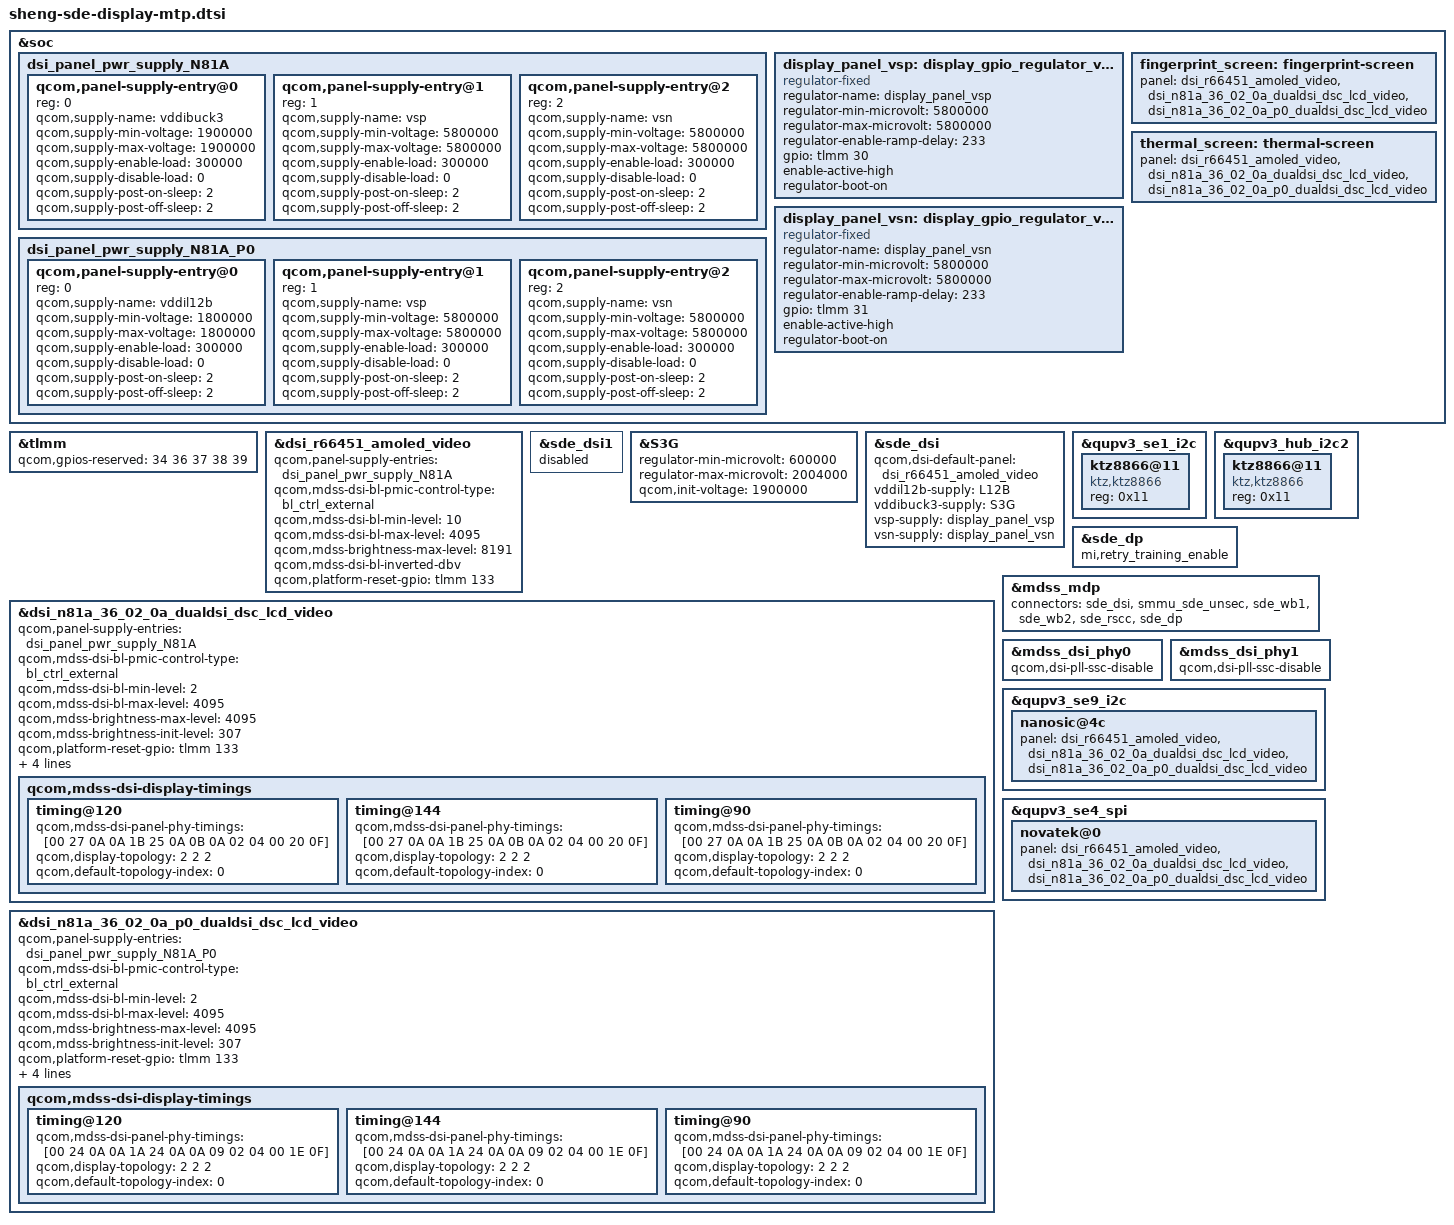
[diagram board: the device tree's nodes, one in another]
#include "kalama-sde-display.dtsi"
#include "dsi-panel-n81a-36-02-0a-dualdsi-dsc-lcd-video.dtsi"
#include "dsi-panel-n81a-36-02-0a-p0-dualdsi-dsc-lcd-video.dtsi"

&soc {
    dsi_panel_pwr_supply_N81A: dsi_panel_pwr_supply_N81A {
        #address-cells = <1>;
        #size-cells = <0>;
        qcom,panel-supply-entry@0 {
            reg = <0>;
            qcom,supply-name = "vddibuck3";
            qcom,supply-min-voltage = <1900000>;
            qcom,supply-max-voltage = <1900000>;
            qcom,supply-enable-load = <300000>;
            qcom,supply-disable-load = <0>;
            qcom,supply-post-on-sleep = <2>;
            qcom,supply-post-off-sleep = <2>;
        };
        qcom,panel-supply-entry@1 {
            reg = <1>;
            qcom,supply-name = "vsp";
            qcom,supply-min-voltage = <5800000>;
            qcom,supply-max-voltage = <5800000>;
            qcom,supply-enable-load = <300000>;
            qcom,supply-disable-load = <0>;
            qcom,supply-post-on-sleep = <2>;
            qcom,supply-post-off-sleep = <2>;
        };
        qcom,panel-supply-entry@2 {
            reg = <2>;
            qcom,supply-name = "vsn";
            qcom,supply-min-voltage = <5800000>;
            qcom,supply-max-voltage = <5800000>;
            qcom,supply-enable-load = <300000>;
            qcom,supply-disable-load = <0>;
            qcom,supply-post-on-sleep = <2>;
            qcom,supply-post-off-sleep = <2>;
        };
    };

    dsi_panel_pwr_supply_N81A_P0: dsi_panel_pwr_supply_N81A_P0 {
        #address-cells = <1>;
        #size-cells = <0>;
        qcom,panel-supply-entry@0 {
            reg = <0>;
            qcom,supply-name = "vddil12b";
            qcom,supply-min-voltage = <1800000>;
            qcom,supply-max-voltage = <1800000>;
            qcom,supply-enable-load = <300000>;
            qcom,supply-disable-load = <0>;
            qcom,supply-post-on-sleep = <2>;
            qcom,supply-post-off-sleep = <2>;
        };
        qcom,panel-supply-entry@1 {
            reg = <1>;
            qcom,supply-name = "vsp";
            qcom,supply-min-voltage = <5800000>;
            qcom,supply-max-voltage = <5800000>;
            qcom,supply-enable-load = <300000>;
            qcom,supply-disable-load = <0>;
            qcom,supply-post-on-sleep = <2>;
            qcom,supply-post-off-sleep = <2>;
        };
        qcom,panel-supply-entry@2 {
            reg = <2>;
            qcom,supply-name = "vsn";
            qcom,supply-min-voltage = <5800000>;
            qcom,supply-max-voltage = <5800000>;
            qcom,supply-enable-load = <300000>;
            qcom,supply-disable-load = <0>;
            qcom,supply-post-on-sleep = <2>;
            qcom,supply-post-off-sleep = <2>;
        };
    };
};

&soc {
    display_panel_vsp: display_gpio_regulator_vsp {
        compatible = "regulator-fixed";
        regulator-name = "display_panel_vsp";
        regulator-min-microvolt = <5800000>;
        regulator-max-microvolt = <5800000>;
        regulator-enable-ramp-delay = <233>;
        gpio = <&tlmm 30 0>;
        enable-active-high;
        regulator-boot-on;
    };

    display_panel_vsn: display_gpio_regulator_vsn {
        compatible = "regulator-fixed";
        regulator-name = "display_panel_vsn";
        regulator-min-microvolt = <5800000>;
        regulator-max-microvolt = <5800000>;
        regulator-enable-ramp-delay = <233>;
        gpio = <&tlmm 31 0>;
        enable-active-high;
        regulator-boot-on;
    };
};

&tlmm {
    qcom,gpios-reserved = <34 36 37 38 39>;
};

&dsi_r66451_amoled_video {
    qcom,panel-supply-entries = <&dsi_panel_pwr_supply_N81A>;
    qcom,mdss-dsi-bl-pmic-control-type = "bl_ctrl_external";
    qcom,mdss-dsi-bl-min-level = <10>;
    qcom,mdss-dsi-bl-max-level = <4095>;
    qcom,mdss-brightness-max-level = <8191>;
    qcom,mdss-dsi-bl-inverted-dbv;
    qcom,platform-reset-gpio = <&tlmm 133 0>;
    /delete-property/qcom,esd-check-enabled;
};

&sde_dsi1 {
    status = "disabled";
    /* release l13b */
    /delete-property/ vci-supply;
};

&S3G {
    regulator-min-microvolt = <600000>;
    regulator-max-microvolt = <2004000>;
    qcom,init-voltage = <1900000>;
};

&sde_dsi {
    qcom,dsi-default-panel = <&dsi_r66451_amoled_video>;
    vddil12b-supply = <&L12B>;
    vddibuck3-supply = <&S3G>;
    vsp-supply = <&display_panel_vsp>;
    vsn-supply = <&display_panel_vsn>;
    /* release l13b */
    /delete-property/ vci-supply;
};

&dsi_n81a_36_02_0a_dualdsi_dsc_lcd_video {
    qcom,panel-supply-entries = <&dsi_panel_pwr_supply_N81A>;
    qcom,mdss-dsi-bl-pmic-control-type = "bl_ctrl_external";
    qcom,mdss-dsi-bl-min-level = <2>;
    qcom,mdss-dsi-bl-max-level = <4095>;
    qcom,mdss-brightness-max-level = <4095>;
    qcom,mdss-brightness-init-level = <307>;
    qcom,platform-reset-gpio = <&tlmm 133 0>;
};

&dsi_n81a_36_02_0a_dualdsi_dsc_lcd_video {
    qcom,dsi-ctrl-num = <0 1>;
    qcom,dsi-phy-num = <0 1>;
    qcom,dsi-select-clocks = "pll_byte_clk0", "pll_dsi_clk0";
    qcom,mdss-dsi-display-timings {
        timing@120 {
            qcom,mdss-dsi-panel-phy-timings = [00 27 0A 0A 1B 25 0A 0B 0A 02 04 00 20 0F];
            qcom,display-topology = <2 2 2>;
            qcom,default-topology-index = <0>;
        };
        timing@144 {
            qcom,mdss-dsi-panel-phy-timings = [00 27 0A 0A 1B 25 0A 0B 0A 02 04 00 20 0F];
            qcom,display-topology = <2 2 2>;
            qcom,default-topology-index = <0>;
        };
        timing@90 {
            qcom,mdss-dsi-panel-phy-timings = [00 27 0A 0A 1B 25 0A 0B 0A 02 04 00 20 0F];
            qcom,display-topology = <2 2 2>;
            qcom,default-topology-index = <0>;
        };
    };
};

&dsi_n81a_36_02_0a_p0_dualdsi_dsc_lcd_video {
    qcom,panel-supply-entries = <&dsi_panel_pwr_supply_N81A_P0>;
    qcom,mdss-dsi-bl-pmic-control-type = "bl_ctrl_external";
    qcom,mdss-dsi-bl-min-level = <2>;
    qcom,mdss-dsi-bl-max-level = <4095>;
    qcom,mdss-brightness-max-level = <4095>;
    qcom,mdss-brightness-init-level = <307>;
    qcom,platform-reset-gpio = <&tlmm 133 0>;
};

&dsi_n81a_36_02_0a_p0_dualdsi_dsc_lcd_video {
    qcom,dsi-ctrl-num = <0 1>;
    qcom,dsi-phy-num = <0 1>;
    qcom,dsi-select-clocks = "pll_byte_clk0", "pll_dsi_clk0";
    qcom,mdss-dsi-display-timings {
        timing@120 {
            qcom,mdss-dsi-panel-phy-timings = [00 24 0A 0A 1A 24 0A 0A 09 02 04 00 1E 0F];
            qcom,display-topology = <2 2 2>;
            qcom,default-topology-index = <0>;
        };
        timing@144 {
            qcom,mdss-dsi-panel-phy-timings = [00 24 0A 0A 1A 24 0A 0A 09 02 04 00 1E 0F];
            qcom,display-topology = <2 2 2>;
            qcom,default-topology-index = <0>;
        };
        timing@90 {
            qcom,mdss-dsi-panel-phy-timings = [00 24 0A 0A 1A 24 0A 0A 09 02 04 00 1E 0F];
            qcom,display-topology = <2 2 2>;
            qcom,default-topology-index = <0>;
        };
    };
};

&qupv3_se1_i2c {
    status = "ok";
    ktz8866@11 {
        compatible = "ktz,ktz8866";
        status = "ok";
        reg = <0x11>;
        //ktz8866,hwen-gpio = <&tlmm 128 0x00>;
        //ktz8866,enp-gpio = <&tlmm 30 0x00>;
        //ktz8866,enn-gpio = <&tlmm 31 0x00>;
        //ktz8866,panelid-gpio = <&tlmm 10 0x00>;
        //ktz8866,backlight-HBM-enable;
    };
};

&qupv3_hub_i2c2 {
    status = "ok";
    ktz8866@11 {
        compatible = "ktz,ktz8866";
        status = "ok";
        reg = <0x11>;
    };
};

&sde_dp  {
    status = "ok";
    mi,retry_training_enable;
};

&sde_dsi1 {
    status = "disabled";
};

&mdss_mdp {
    connectors = <&sde_dsi &smmu_sde_unsec &sde_wb1 &sde_wb2 &sde_rscc &sde_dp>;
};

/* close ssc */
&mdss_dsi_phy0 {
    qcom,dsi-pll-ssc-disable;
};

&mdss_dsi_phy1 {
    qcom,dsi-pll-ssc-disable;
};

&soc {
    fingerprint_screen: fingerprint-screen {
        panel = <&dsi_r66451_amoled_video
                 &dsi_n81a_36_02_0a_dualdsi_dsc_lcd_video
                 &dsi_n81a_36_02_0a_p0_dualdsi_dsc_lcd_video>;
    };
};

&soc {
	thermal_screen: thermal-screen {
        panel = <&dsi_r66451_amoled_video
                 &dsi_n81a_36_02_0a_dualdsi_dsc_lcd_video
                 &dsi_n81a_36_02_0a_p0_dualdsi_dsc_lcd_video>;
    };
};

/* keyboard start */
&qupv3_se9_i2c {
    nanosic@4c{
        panel = <&dsi_r66451_amoled_video
                 &dsi_n81a_36_02_0a_dualdsi_dsc_lcd_video
                 &dsi_n81a_36_02_0a_p0_dualdsi_dsc_lcd_video>;
    };
};
/* keyboard end */
/* touch start */
&qupv3_se4_spi {
    novatek@0 {
        panel = <&dsi_r66451_amoled_video
                 &dsi_n81a_36_02_0a_dualdsi_dsc_lcd_video
                 &dsi_n81a_36_02_0a_p0_dualdsi_dsc_lcd_video>;
    };
};
/* touch end */
